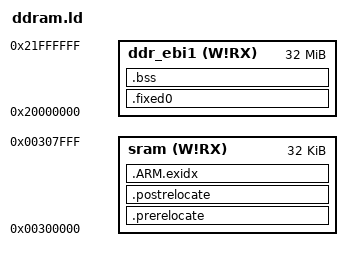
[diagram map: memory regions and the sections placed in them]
/* ----------------------------------------------------------------------------
 *         ATMEL Microcontroller Software Support
 * ----------------------------------------------------------------------------
 * Copyright (c) 2010, Atmel Corporation
 *
 * All rights reserved.
 *
 * Redistribution and use in source and binary forms, with or without
 * modification, are permitted provided that the following conditions are met:
 *
 * - Redistributions of source code must retain the above copyright notice,
 * this list of conditions and the disclaimer below.
 *
 * Atmel's name may not be used to endorse or promote products derived from
 * this software without specific prior written permission.
 *
 * DISCLAIMER: THIS SOFTWARE IS PROVIDED BY ATMEL "AS IS" AND ANY EXPRESS OR
 * IMPLIED WARRANTIES, INCLUDING, BUT NOT LIMITED TO, THE IMPLIED WARRANTIES OF
 * MERCHANTABILITY, FITNESS FOR A PARTICULAR PURPOSE AND NON-INFRINGEMENT ARE
 * DISCLAIMED. IN NO EVENT SHALL ATMEL BE LIABLE FOR ANY DIRECT, INDIRECT,
 * INCIDENTAL, SPECIAL, EXEMPLARY, OR CONSEQUENTIAL DAMAGES (INCLUDING, BUT NOT
 * LIMITED TO, PROCUREMENT OF SUBSTITUTE GOODS OR SERVICES; LOSS OF USE, DATA,
 * OR PROFITS; OR BUSINESS INTERRUPTION) HOWEVER CAUSED AND ON ANY THEORY OF
 * LIABILITY, WHETHER IN CONTRACT, STRICT LIABILITY, OR TORT (INCLUDING
 * NEGLIGENCE OR OTHERWISE) ARISING IN ANY WAY OUT OF THE USE OF THIS SOFTWARE,
 * EVEN IF ADVISED OF THE POSSIBILITY OF SUCH DAMAGE.
 * ----------------------------------------------------------------------------
 */

/*------------------------------------------------------------------------------
 *      Linker script for running in internal DDRAM on the SAM9G15
 *----------------------------------------------------------------------------*/

OUTPUT_FORMAT("elf32-littlearm", "elf32-littlearm", "elf32-littlearm")
OUTPUT_ARCH(arm)
ENTRY(entry)
SEARCH_DIR(.)

/* Memory Spaces Definitions */
MEMORY
{
    sram (W!RX) : ORIGIN = 0x300000, LENGTH = 0x8000 /* sram, 32K */
    ddr_ebi1 (W!RX) : ORIGIN = 0x20000000, LENGTH = 32M
}

/* Section Definitions */ 
SECTIONS 
{ 
    /*PROVIDE (_executable_start = 0x20000000); . = 0x20000000;*/
    /*.reset : {*(.textEntry) } >ddr_ebi1  AT> ddr_ebi1:ddr_ebi1  */
    
    .fixed0 : 
    { 
        . = ALIGN(4);
        _sfixed = .;
        *(.textEntry)
        *(.text*)
        *(.text .gnu.linkonce.t.*)
        *(.glue_7t) *(.glue_7)
        *(.CP15_*)
        *(.rodata .rodata* .gnu.linkonce.r.*)
        *(.ARM.extab* .gnu.linkonce.armextab.*)

        /* Support C constructors, and C destructors in both user code
           and the C library. This also provides support for C++ code. */
        . = ALIGN(4);
        KEEP(*(.init))
        . = ALIGN(4);
        __preinit_array_start = .;
        KEEP (*(.preinit_array))
        __preinit_array_end = .;

        . = ALIGN(4);
        __init_array_start = .;
        KEEP (*(SORT(.init_array.*)))
        KEEP (*(.init_array))
        __init_array_end = .;

        . = ALIGN(0x4);
        KEEP (*crtbegin.o(.ctors))
        KEEP (*(EXCLUDE_FILE (*crtend.o) .ctors))
        KEEP (*(SORT(.ctors.*)))
        KEEP (*crtend.o(.ctors))

        . = ALIGN(4);
        KEEP(*(.fini))

        . = ALIGN(4);
        __fini_array_start = .;
        KEEP (*(.fini_array))
        KEEP (*(SORT(.fini_array.*)))
        __fini_array_end = .;

        KEEP (*crtbegin.o(.dtors))
        KEEP (*(EXCLUDE_FILE (*crtend.o) .dtors))
        KEEP (*(SORT(.dtors.*)))
        KEEP (*crtend.o(.dtors))
        *(.data .data.*);
        . = ALIGN(4);
        _efixed = .;            /* End of text section */
    } > ddr_ebi1

    . = ALIGN(4); 
    _etext = .;


    .prerelocate : AT (_etext)
    {
        . = ALIGN(4);
        _sprerelocate = .;
        . = ALIGN(4);
        _eprerelocate = .;
    } >sram

    .postrelocate : AT (_efixed + SIZEOF(.prerelocate))
    {
        . = ALIGN(4);
        _spostrelocate = .;
        *(.vectors);
        *(.ramfunc)
        . = ALIGN(4);
        _epostrelocate = .;
    } >sram

    /* .bss section which is used for uninitialized data */ 
    .bss (NOLOAD) :
    { 
       . = ALIGN(4);
        _sbss = . ;
        _szero = .;
        *(.bss .bss.*)
        *(COMMON)
        . = ALIGN(4);
        _ebss = . ;
        _ezero = .;
    } > ddr_ebi1

    /* .ARM.exidx is sorted, so has to go in its own output section.  */
    PROVIDE_HIDDEN (__exidx_start = .);
    .ARM.exidx :
    {
      *(.ARM.exidx* .gnu.linkonce.armexidx.*)
    } > sram
    PROVIDE_HIDDEN (__exidx_end = .);

    PROVIDE(_heap = 0x21000000);
    _sstack = 0x20000000 + 32 * 1024 * 1024;
    . = ALIGN(4); 

    _end = . ; 
}
